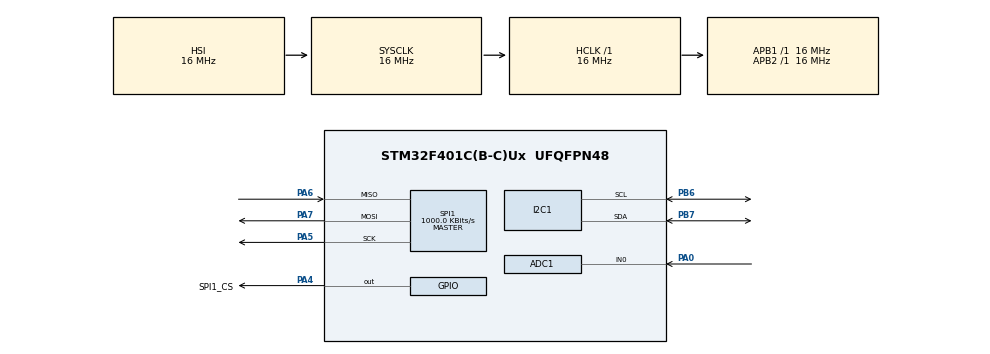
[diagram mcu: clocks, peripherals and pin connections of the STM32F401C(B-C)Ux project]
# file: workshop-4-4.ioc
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ADC1.Channel-0\#ChannelRegularConversion=ADC_CHANNEL_0
ADC1.DMAContinuousRequests=ENABLE
ADC1.ExternalTrigConv=ADC_EXTERNALTRIGCONV_T2_TRGO
ADC1.NbrOfConversionFlag=1
ADC1.Rank-0\#ChannelRegularConversion=1
ADC1.SamplingTime-0\#ChannelRegularConversion=ADC_SAMPLETIME_480CYCLES
ADC1.master=1
Dma.ADC1.0.Direction=DMA_PERIPH_TO_MEMORY
Dma.ADC1.0.FIFOMode=DMA_FIFOMODE_DISABLE
Dma.ADC1.0.Instance=DMA2_Stream0
Dma.ADC1.0.MemDataAlignment=DMA_MDATAALIGN_HALFWORD
Dma.ADC1.0.MemInc=DMA_MINC_ENABLE
Dma.ADC1.0.Mode=DMA_CIRCULAR
Dma.ADC1.0.PeriphDataAlignment=DMA_PDATAALIGN_HALFWORD
Dma.ADC1.0.PeriphInc=DMA_PINC_DISABLE
Dma.ADC1.0.Priority=DMA_PRIORITY_LOW
Dma.Request0=ADC1
Mcu.Family=STM32F4
Mcu.Name=STM32F401C(B-C)Ux
Mcu.Package=UFQFPN48
NVIC.DMA2_Stream0_IRQn=true\:0\:0\:false\:false\:true\:false\:true\:true
NVIC.PriorityGroup=NVIC_PRIORITYGROUP_4
PA0-WKUP.Signal=ADCx_IN0
PA13.Mode=Serial_Wire
PA13.Signal=SYS_JTMS-SWDIO
PA14.Mode=Serial_Wire
PA14.Signal=SYS_JTCK-SWCLK
PA4.GPIO_Label=SPI1_CS
PA4.GPIO_Speed=GPIO_SPEED_FREQ_VERY_HIGH
PA4.Signal=GPIO_Output
PA5.Mode=Full_Duplex_Master
PA5.Signal=SPI1_SCK
PA6.Mode=Full_Duplex_Master
PA6.Signal=SPI1_MISO
PA7.Mode=Full_Duplex_Master
PA7.Signal=SPI1_MOSI
PB6.Mode=I2C
PB6.Signal=I2C1_SCL
PB7.Mode=I2C
PB7.Signal=I2C1_SDA
ProjectManager.HeapSize=0x200
ProjectManager.StackSize=0x400
ProjectManager.TargetToolchain=STM32CubeIDE
RCC.AHBFreq_Value=16000000
RCC.APB1Freq_Value=16000000
RCC.APB2Freq_Value=16000000
RCC.CortexFreq_Value=16000000
RCC.HSE_VALUE=25000000
RCC.HSI_VALUE=16000000
RCC.LSE_VALUE=32768
RCC.SYSCLKFreq_VALUE=16000000
RCC.VCOOutputFreq_Value=192000000
SH.ADCx_IN0.0=ADC1_IN0,IN0
SPI1.BaudRatePrescaler=SPI_BAUDRATEPRESCALER_16
SPI1.CalculateBaudRate=1000.0 KBits/s
SPI1.Direction=SPI_DIRECTION_2LINES
SPI1.Mode=SPI_MODE_MASTER
SPI1.VirtualNSS=VM_NSSSOFT
SPI1.VirtualType=VM_MASTER
TIM2.Period=49
TIM2.Prescaler=1599
TIM2.TIM_MasterOutputTrigger=TIM_TRGO_UPDATE
VP_TIM2_VS_ClockSourceINT.Mode=Internal
board=custom

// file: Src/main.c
/* USER CODE BEGIN Header */
/**
  ******************************************************************************
  * @file           : main.c
  * @brief          : Main program body
  ******************************************************************************
  */
/* USER CODE END Header */
#include "main.h"

/* USER CODE BEGIN Includes */
// Прикладні модулі: кожен володіє своїм шматком роботи і сам стежить за своїм
// таймером. Тут лишається тільки підняти периферію і крутити цикл.
#include "i2c_bus.h"        // аварійне звільнення/відновлення шини I2C
#include "display_ui.h"     // кадр на OLED: годинник, адреси, T/RH/P, світло, лінк
#include "telemetry_link.h" // SPI-master: віддає кадр телеметрії рабу ESP32-C3
#include "sensor_stream.h"  // ADC(DMA) + RTC + BME280 -> останні покази датчиків
/* USER CODE END Includes */

/* USER CODE BEGIN PD */
// Налаштування (адреси, розкладка, періоди) винесено в config.h
/* USER CODE END PD */

ADC_HandleTypeDef hadc1;
DMA_HandleTypeDef hdma_adc1;

I2C_HandleTypeDef hi2c1;

SPI_HandleTypeDef hspi1;

TIM_HandleTypeDef htim2;

/* USER CODE BEGIN PV */
// Стан прикладного рівня тримають самі модулі (display_ui, sensor_stream,
// telemetry_link) — тут лише хендли периферії з CubeMX вище.
/* USER CODE END PV */

void SystemClock_Config(void);
static void MX_GPIO_Init(void);
static void MX_DMA_Init(void);
static void MX_ADC1_Init(void);
static void MX_I2C1_Init(void);
static void MX_SPI1_Init(void);
static void MX_TIM2_Init(void);

/* USER CODE BEGIN 0 */
// Прикладна логіка живе в модулях поруч: кадр на OLED зі сканером шини
// (display_ui), відновлення шини I2C (i2c_bus), опитування датчиків
// (sensor_stream) і SPI-master (telemetry_link).
// Тут лишається лише те, що генерує CubeMX: старт периферії й головний цикл.
/* USER CODE END 0 */

int main(void)
{

  /* MCU Configuration--------------------------------------------------------*/

  /* Reset of all peripherals, Initializes the Flash interface and the Systick. */
  HAL_Init();

  /* Configure the system clock */
  SystemClock_Config();

  /* Initialize all configured peripherals */
  MX_GPIO_Init();
  MX_DMA_Init();
  MX_ADC1_Init();
  MX_I2C1_Init();
  MX_SPI1_Init();
  MX_TIM2_Init();
  /* USER CODE BEGIN 2 */
  // Шина могла лишитись захопленою ще з минулого сеансу: якщо обмін обірвався
  // посеред байта, раб тримає SDA і скидання МК він не бачив — саме тому плата
  // піднімалась мертвою і оживала лише після зняття живлення з дисплея. Тому
  // ПЕРШИМ ділом доклацуємо шину, інакше і дисплей, і датчики нижче отримають
  // HAL_BUSY і не піднімуться.
  I2CBus_Release();
  MX_I2C1_Init();   // повертаємо PB6/PB7 з ручного GPIO назад у AF4

  // Кадр на OLED-дисплеї на тій самій шині I2C1 (параметри — у config.h).
  DisplayUI_Init(&hi2c1);

  // SPI1 як master: раз на секунду віддає кадр телеметрії рабу ESP32-C3
  // (PA4 = CS, PA5..PA7 = SCK/MISO/MOSI).
  TelemetryLink_Init();

  // Опитування датчиків: світло (ADC через TIM2+DMA), час (DS1307) і
  // T/RH/P (BME280). Має йти після MX_ADC1_Init/MX_I2C1_Init.
  SensorStream_Init();
  /* USER CODE END 2 */

  /* Infinite loop */
  /* USER CODE BEGIN WHILE */
  while (1)
  {
    // Кожен модуль неблокуюче перевіряє свій таймер (HAL_GetTick) і виконує
    // роботу лише коли настав його період — деталі у відповідному *.c.
    SensorStream_Poll();   // ADC(DMA) + RTC (1 с) + BME280 (1 с)
    TelemetryLink_Poll();  // кадр телеметрії по SPI рабу ESP32-C3 (1 с)
    DisplayUI_Poll();      // сканування шини (10 с) + кадр на екрані (1 с)

    /* USER CODE END WHILE */

    /* USER CODE BEGIN 3 */
    // Тут можна додати інший код, який має виконуватись постійно,
    // наприклад, перевірка кнопок або мигання світлодіодом.
  }
  /* USER CODE END 3 */
}

void SystemClock_Config(void)
{
  RCC_OscInitTypeDef RCC_OscInitStruct = {0};
  RCC_ClkInitTypeDef RCC_ClkInitStruct = {0};

  /** Configure the main internal regulator output voltage
  */
  __HAL_RCC_PWR_CLK_ENABLE();
  __HAL_PWR_VOLTAGESCALING_CONFIG(PWR_REGULATOR_VOLTAGE_SCALE2);

  /** Initializes the RCC Oscillators according to the specified parameters
  * in the RCC_OscInitTypeDef structure.
  */
  RCC_OscInitStruct.OscillatorType = RCC_OSCILLATORTYPE_HSI;
  RCC_OscInitStruct.HSIState = RCC_HSI_ON;
  RCC_OscInitStruct.HSICalibrationValue = RCC_HSICALIBRATION_DEFAULT;
  RCC_OscInitStruct.PLL.PLLState = RCC_PLL_NONE;
  if (HAL_RCC_OscConfig(&RCC_OscInitStruct) != HAL_OK)
  {
    Error_Handler();
  }

  /** Initializes the CPU, AHB and APB buses clocks
  */
  RCC_ClkInitStruct.ClockType = RCC_CLOCKTYPE_HCLK|RCC_CLOCKTYPE_SYSCLK
                              |RCC_CLOCKTYPE_PCLK1|RCC_CLOCKTYPE_PCLK2;
  RCC_ClkInitStruct.SYSCLKSource = RCC_SYSCLKSOURCE_HSI;
  RCC_ClkInitStruct.AHBCLKDivider = RCC_SYSCLK_DIV1;
  RCC_ClkInitStruct.APB1CLKDivider = RCC_HCLK_DIV1;
  RCC_ClkInitStruct.APB2CLKDivider = RCC_HCLK_DIV1;

  if (HAL_RCC_ClockConfig(&RCC_ClkInitStruct, FLASH_LATENCY_0) != HAL_OK)
  {
    Error_Handler();
  }
}

static void MX_ADC1_Init(void)
{

  ADC_ChannelConfTypeDef sConfig = {0};

  /** Configure the global features of the ADC (Clock, Resolution, Data Alignment and number of conversion)
  */
  hadc1.Instance = ADC1;
  hadc1.Init.ClockPrescaler = ADC_CLOCK_SYNC_PCLK_DIV2;
  hadc1.Init.Resolution = ADC_RESOLUTION_12B;
  hadc1.Init.ScanConvMode = DISABLE;
  hadc1.Init.ContinuousConvMode = DISABLE;
  hadc1.Init.DiscontinuousConvMode = DISABLE;
  hadc1.Init.ExternalTrigConvEdge = ADC_EXTERNALTRIGCONVEDGE_RISING;
  hadc1.Init.ExternalTrigConv = ADC_EXTERNALTRIGCONV_T2_TRGO;
  hadc1.Init.DataAlign = ADC_DATAALIGN_RIGHT;
  hadc1.Init.NbrOfConversion = 1;
  hadc1.Init.DMAContinuousRequests = ENABLE;
  hadc1.Init.EOCSelection = ADC_EOC_SINGLE_CONV;
  if (HAL_ADC_Init(&hadc1) != HAL_OK)
  {
    Error_Handler();
  }

  /** Configure for the selected ADC regular channel its corresponding rank in the sequencer and its sample time.
  */
  sConfig.Channel = ADC_CHANNEL_0;
  sConfig.Rank = 1;
  sConfig.SamplingTime = ADC_SAMPLETIME_480CYCLES;
  if (HAL_ADC_ConfigChannel(&hadc1, &sConfig) != HAL_OK)
  {
    Error_Handler();
  }

}

static void MX_I2C1_Init(void)
{

  hi2c1.Instance = I2C1;
  hi2c1.Init.ClockSpeed = 100000;
  hi2c1.Init.DutyCycle = I2C_DUTYCYCLE_2;
  hi2c1.Init.OwnAddress1 = 0;
  hi2c1.Init.AddressingMode = I2C_ADDRESSINGMODE_7BIT;
  hi2c1.Init.DualAddressMode = I2C_DUALADDRESS_DISABLE;
  hi2c1.Init.OwnAddress2 = 0;
  hi2c1.Init.GeneralCallMode = I2C_GENERALCALL_DISABLE;
  hi2c1.Init.NoStretchMode = I2C_NOSTRETCH_DISABLE;
  if (HAL_I2C_Init(&hi2c1) != HAL_OK)
  {
    Error_Handler();
  }

}

static void MX_SPI1_Init(void)
{

  /* SPI1 parameter configuration*/
  hspi1.Instance = SPI1;
  hspi1.Init.Mode = SPI_MODE_MASTER;
  hspi1.Init.Direction = SPI_DIRECTION_2LINES;
  hspi1.Init.DataSize = SPI_DATASIZE_8BIT;
  hspi1.Init.CLKPolarity = SPI_POLARITY_LOW;
  hspi1.Init.CLKPhase = SPI_PHASE_1EDGE;
  hspi1.Init.NSS = SPI_NSS_SOFT;
  hspi1.Init.BaudRatePrescaler = SPI_BAUDRATEPRESCALER_16;
  hspi1.Init.FirstBit = SPI_FIRSTBIT_MSB;
  hspi1.Init.TIMode = SPI_TIMODE_DISABLE;
  hspi1.Init.CRCCalculation = SPI_CRCCALCULATION_DISABLE;
  hspi1.Init.CRCPolynomial = 10;
  if (HAL_SPI_Init(&hspi1) != HAL_OK)
  {
    Error_Handler();
  }
  /* USER CODE BEGIN SPI1_Init 2 */
  // Ця плата тепер MASTER, а раніше (workshop-4-miniproject) була slave — при
  // перегенерації з .ioc звірте саме ці три поля:
  //   Mode              SPI_MODE_MASTER      хто видає такти
  //   NSS               SPI_NSS_SOFT         CS веде GPIO PA4, а не периферія.
  //                     Апаратний NSS-output на F4 смикає CS між БАЙТАМИ, а не
  //                     на весь обмін — раб побачив би 32 транзакції по одному
  //                     байту замість одного 32-байтного кадру.
  //   BaudRatePrescaler /16 -> 16 МГц APB2 / 16 = 1 МГц SCK
  // Режим 0 (CPOL=0, CPHA=0) і MSB-first мають збігатися з налаштуванням раба
  // в espc3/src/hardware/SpiSlave.hpp.
  /* USER CODE END SPI1_Init 2 */

}

static void MX_TIM2_Init(void)
{

  TIM_ClockConfigTypeDef sClockSourceConfig = {0};
  TIM_MasterConfigTypeDef sMasterConfig = {0};

  htim2.Instance = TIM2;
  htim2.Init.Prescaler = 1599;
  htim2.Init.CounterMode = TIM_COUNTERMODE_UP;
  htim2.Init.Period = 49;
  htim2.Init.ClockDivision = TIM_CLOCKDIVISION_DIV1;
  htim2.Init.AutoReloadPreload = TIM_AUTORELOAD_PRELOAD_DISABLE;
  if (HAL_TIM_Base_Init(&htim2) != HAL_OK)
  {
    Error_Handler();
  }
  sClockSourceConfig.ClockSource = TIM_CLOCKSOURCE_INTERNAL;
  if (HAL_TIM_ConfigClockSource(&htim2, &sClockSourceConfig) != HAL_OK)
  {
    Error_Handler();
  }
  sMasterConfig.MasterOutputTrigger = TIM_TRGO_UPDATE;
  sMasterConfig.MasterSlaveMode = TIM_MASTERSLAVEMODE_DISABLE;
  if (HAL_TIMEx_MasterConfigSynchronization(&htim2, &sMasterConfig) != HAL_OK)
  {
    Error_Handler();
  }

}

static void MX_DMA_Init(void)
{

  /* DMA controller clock enable */
  __HAL_RCC_DMA2_CLK_ENABLE();

  /* DMA interrupt init */
  /* DMA2_Stream0_IRQn interrupt configuration */
  HAL_NVIC_SetPriority(DMA2_Stream0_IRQn, 0, 0);
  HAL_NVIC_EnableIRQ(DMA2_Stream0_IRQn);

}

static void MX_GPIO_Init(void)
{
  GPIO_InitTypeDef GPIO_InitStruct = {0};

  /* GPIO Ports Clock Enable */
  __HAL_RCC_GPIOA_CLK_ENABLE();
  __HAL_RCC_GPIOB_CLK_ENABLE();

  /*Configure GPIO pin Output Level */
  HAL_GPIO_WritePin(SPI1_CS_GPIO_Port, SPI1_CS_Pin, GPIO_PIN_RESET);

  /*Configure GPIO pin : SPI1_CS_Pin */
  GPIO_InitStruct.Pin = SPI1_CS_Pin;
  GPIO_InitStruct.Mode = GPIO_MODE_OUTPUT_PP;
  GPIO_InitStruct.Pull = GPIO_NOPULL;
  GPIO_InitStruct.Speed = GPIO_SPEED_FREQ_VERY_HIGH;
  HAL_GPIO_Init(SPI1_CS_GPIO_Port, &GPIO_InitStruct);

  /* USER CODE BEGIN MX_GPIO_Init_2 */
  // CS піднято ДО HAL_SPI_Init нижче і до будь-якого обміну — порядок тут
  // важливий. Поки пін не заданий, він плаває, і раб може прийняти шум за
  // початок кадру: рівно ця історія (плаваючий CS) у попередньому проєкті
  // ламала сусідній пристрій на спільній шині.
  /* USER CODE END MX_GPIO_Init_2 */
}

void Error_Handler(void)
{
  __disable_irq();
  while (1)
  {
  }
}
